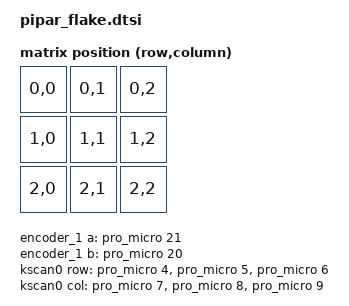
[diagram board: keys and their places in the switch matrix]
/*
 * Copyright (c) 2022 The ZMK Contributors
 *
 * SPDX-License-Identifier: MIT
 */

#include <dt-bindings/zmk/matrix_transform.h>

/ {
  chosen {
    zmk,kscan = &kscan0;
    zmk,matrix-transform = &default_transform;
    zmk,backlight = &backlight;
    zephyr,display = &oled;
  };

  encoder_1: encoder_1 {
    compatible = "alps,ec11";
    a-gpios = <&pro_micro 21 (GPIO_ACTIVE_HIGH | GPIO_PULL_UP)>;
    b-gpios = <&pro_micro 20 (GPIO_ACTIVE_HIGH | GPIO_PULL_UP)>;
    steps = <60>;
    status = "disabled";
  };


  kscan0: kscan_0 {
    compatible = "zmk,kscan-gpio-matrix";
    diode-direction = "col2row";
    wakeup-source;

    row-gpios
      = <&pro_micro 4 (GPIO_ACTIVE_HIGH | GPIO_PULL_DOWN)>
      , <&pro_micro 5 (GPIO_ACTIVE_HIGH | GPIO_PULL_DOWN)>
      , <&pro_micro 6 (GPIO_ACTIVE_HIGH | GPIO_PULL_DOWN)>
      ;

    col-gpios
      = <&pro_micro 7 GPIO_ACTIVE_HIGH>
      , <&pro_micro 8 GPIO_ACTIVE_HIGH>
      , <&pro_micro 9 GPIO_ACTIVE_HIGH>
      ;
    };

  default_transform: keymap_transform_0 {
    compatible = "zmk,matrix-transform";
    columns = <3>;
    rows = <3>;
    map = <
            RC(0, 0) RC(0, 1) RC(0, 2)
            RC(1, 0) RC(1, 1) RC(1, 2)
            RC(2, 0) RC(2, 1) RC(2, 2)
    >;
  };

  
  backlight: pwmleds {
      compatible = "pwm-leds";
      pwm_led_0 {
          pwms = <&pwm0 0 PWM_MSEC(10) PWM_POLARITY_NORMAL>;
      };
  };

};

&pwm0 {
    status = "okay";
    pinctrl-0 = <&pwm0_default>;
    pinctrl-1 = <&pwm0_sleep>;
    pinctrl-names = "default", "sleep";
};

&pro_micro_i2c {
    status = "okay";

    oled: ssd1306@3c {
        compatible = "solomon,ssd1306fb";
        reg = <0x3c>;
        width = <128>;
        height = <32>;
        segment-offset = <0>;
        page-offset = <0>;
        display-offset = <0>;
        multiplex-ratio = <31>;
        com-sequential;
        inversion-on;
        prechargep = <0x22>;
    };
};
